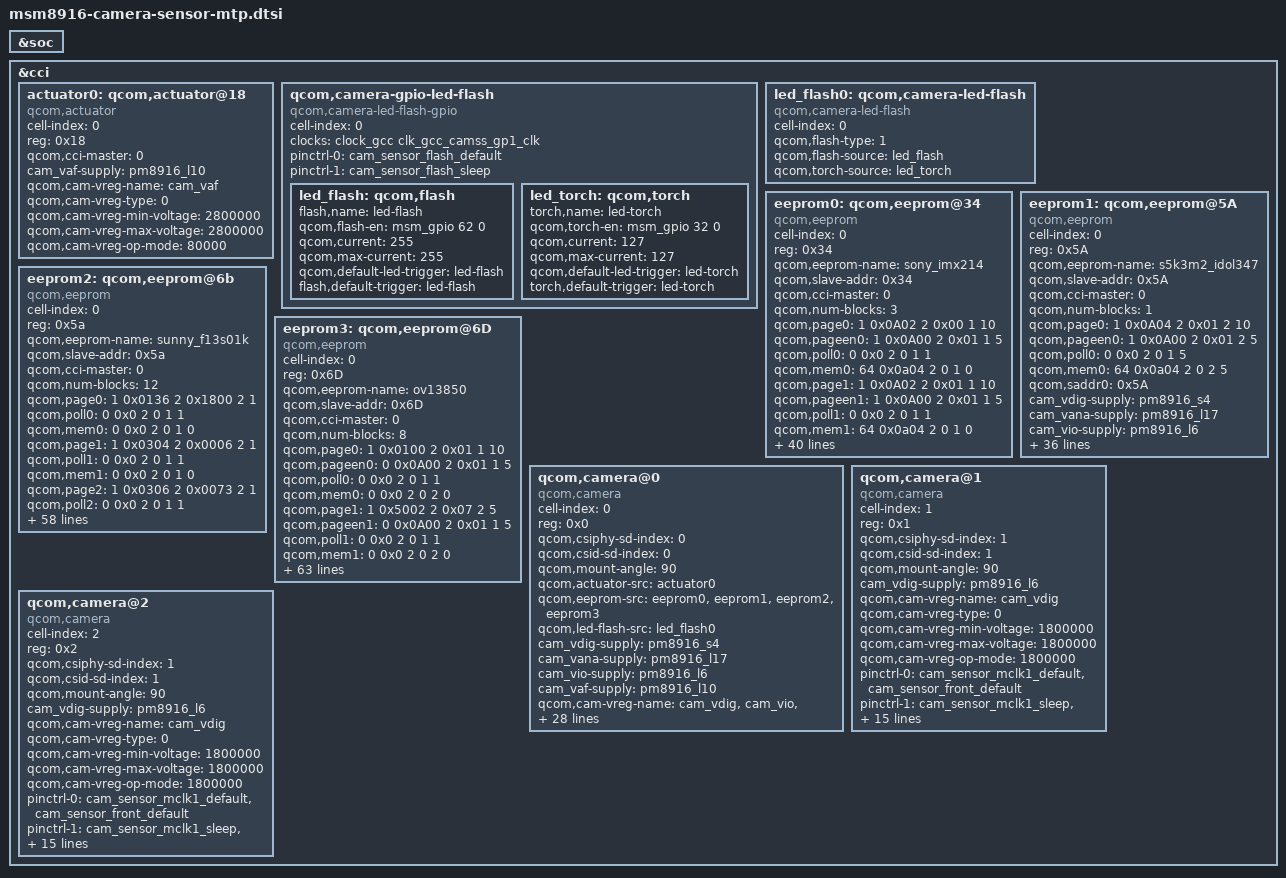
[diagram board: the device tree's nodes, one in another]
/*
 * Copyright (c) 2014-2015, The Linux Foundation. All rights reserved.
 *
 * This program is free software; you can redistribute it and/or modify
 * it under the terms of the GNU General Public License version 2 and
 * only version 2 as published by the Free Software Foundation.
 *
 * This program is distributed in the hope that it will be useful,
 * but WITHOUT ANY WARRANTY; without even the implied warranty of
 * MERCHANTABILITY or FITNESS FOR A PARTICULAR PURPOSE.  See the
 * GNU General Public License for more details.
 */

&soc {
};

&cci {

	actuator0: qcom,actuator@18 {
		cell-index = <0>;
		reg = <0x18>;
		compatible = "qcom,actuator";
		qcom,cci-master = <0>;
		cam_vaf-supply = <&pm8916_l10>;
		qcom,cam-vreg-name = "cam_vaf";
		qcom,cam-vreg-type = <0>;
		qcom,cam-vreg-min-voltage = <2800000>;
		qcom,cam-vreg-max-voltage = <2800000>;
		qcom,cam-vreg-op-mode = <80000>;
	};

	qcom,camera-gpio-led-flash {
		cell-index = <0>;
		compatible = "qcom,camera-led-flash-gpio";
		status = "okay";
 	clocks = <&clock_gcc clk_gcc_camss_gp1_clk>;
		clock-names = "cam_sensor_flash";
		pinctrl-names = "default", "sleep";
		pinctrl-0 = <&cam_sensor_flash_default>;
		pinctrl-1 = <&cam_sensor_flash_sleep>;
		led_flash: qcom,flash {
			flash,name = "led-flash";
			qcom,flash-en = <&msm_gpio 62 0>;
			qcom,current = <255>;
			qcom,max-current = <255>;
            		qcom,default-led-trigger = "led-flash";
			flash,default-trigger = "led-flash";
		};
		led_torch: qcom,torch {
			torch,name = "led-torch";
			qcom,torch-en = <&msm_gpio 32 0>;
			qcom,current = <127>;
			qcom,max-current = <127>;
            		qcom,default-led-trigger = "led-torch";
			torch,default-trigger = "led-torch";
		};
	};

	led_flash0: qcom,camera-led-flash {
		cell-index = <0>;
		compatible = "qcom,camera-led-flash";
		qcom,flash-type = <1>;
		qcom,flash-source = <&led_flash>;
		qcom,torch-source = <&led_torch>;
	};

eeprom0: qcom,eeprom@34 {
		 cell-index = <0>;
		 reg = <0x34>;
		 qcom,eeprom-name = "sony_imx214";
		 compatible = "qcom,eeprom";
		 qcom,slave-addr = <0x34>;
		 qcom,cci-master = <0>;
		 qcom,num-blocks = <3>;

		 qcom,page0 = <1 0x0A02 2 0x00 1 10>;
        	 qcom,pageen0 = <1 0x0A00 2 0x01 1 5>; 
		 qcom,poll0 = <0 0x0 2 0 1 1>;
		 qcom,mem0 = <64 0x0a04 2 0 1 0>;

 		 qcom,page1 = <1 0x0A02 2 0x01 1 10>;
        	 qcom,pageen1 = <1 0x0A00 2 0x01 1 5>; 
		 qcom,poll1 = <0 0x0 2 0 1 1>;
		 qcom,mem1 = <64 0x0a04 2 0 1 0>;

		 qcom,page2 = <1 0x0A02 2 0x02 1 10>;
        	 qcom,pageen2 = <1 0x0A00 2 0x01 1 5>; 
		 qcom,poll2 = <0 0x0 2 0 1 1>;
		 qcom,mem2 = <64 0x0a04 2 0 1 0>;

		cam_vdig-supply = <&pm8916_s4>;
		cam_vana-supply = <&pm8916_l17>;
		cam_vio-supply = <&pm8916_l6>;
		cam_vaf-supply = <&pm8916_l10>;
		 qcom,cam-vreg-name = "cam_vdig", "cam_vio", "cam_vana",
							"cam_vaf";
		qcom,cam-vreg-type = <0 1 0 0>;
		qcom,cam-vreg-min-voltage = <1850000 0 2700000 2800000>;
		qcom,cam-vreg-max-voltage = <1850000 0 2700000 2800000>;
		qcom,cam-vreg-op-mode = <200000 0 80000 100000>;
			pinctrl-names = "cam_default", "cam_suspend";
		pinctrl-0 = <&cam_sensor_mclk0_default
				&cam_sensor_rear_default>;
		pinctrl-1 = <&cam_sensor_mclk0_sleep &cam_sensor_rear_sleep>;
		

		 gpios = <&msm_gpio 26 0>,
			<&msm_gpio 35 0>,
			<&msm_gpio 34 0>,
			<&msm_gpio 109 0>,
			<&msm_gpio 108 0>;
		qcom,gpio-reset = <1>;
		qcom,gpio-standby = <2>;
		qcom,gpio-vdig = <3>;
		qcom,gpio-vana = <4>;
		qcom,gpio-req-tbl-num = <0 1 2 3 4>;
		qcom,gpio-req-tbl-flags = <1 0 0 0 0>;
		qcom,gpio-req-tbl-label = "CAMIF_MCLK",
			"CAM_RESET1",
			"CAM_STANDBY",
			"CAM_GPIO_VDIG",
			"CAM_GPIO_VANA";
			
	 	qcom,cam-power-seq-type = "sensor_gpio","sensor_gpio", "sensor_gpio" , "sensor_clk";
	        qcom,cam-power-seq-val = "sensor_gpio_standby","sensor_gpio_vdig", "sensor_gpio_standby","sensor_cam_mclk";
	        qcom,cam-power-seq-cfg-val = <0 1 1 24000000>;
	        qcom,cam-power-seq-delay = <10 10 10 5>;
 
		
		status = "ok";
        	clocks = <&clock_gcc clk_mclk0_clk_src>,
                	<&clock_gcc clk_gcc_camss_mclk0_clk>;
        	clock-names = "cam_src_clk", "cam_clk"; 

	};

eeprom1: qcom,eeprom@5A {
		 cell-index = <0>;
		 reg = <0x5A>;
		 qcom,eeprom-name = "s5k3m2_idol347";
		 compatible = "qcom,eeprom";
		 qcom,slave-addr = <0x5A>;
		 qcom,cci-master = <0>;
		 qcom,num-blocks = <1>;

		 qcom,page0 = <1 0x0A04 2 0x01 2 10>;
        	 qcom,pageen0 = <1 0x0A00 2 0x01 2 5>; 
		 qcom,poll0 = <0 0x0 2 0 1 5>;
		 qcom,mem0 = <64 0x0a04 2 0 2 5>;
        	 qcom,saddr0 = <0x5A>;


		cam_vdig-supply = <&pm8916_s4>;
		cam_vana-supply = <&pm8916_l17>;
		cam_vio-supply = <&pm8916_l6>;
		cam_vaf-supply = <&pm8916_l10>;
		qcom,cam-vreg-name = "cam_vdig", "cam_vio", "cam_vana",
							"cam_vaf";
		qcom,cam-vreg-type = <0 1 0 0>;
		qcom,cam-vreg-min-voltage = <1100000 0 2700000 2800000>;
		qcom,cam-vreg-max-voltage = <1100000 0 2700000 2800000>;
		qcom,cam-vreg-op-mode = <200000 0 80000 100000>;
			pinctrl-names = "cam_default", "cam_suspend";
		pinctrl-0 = <&cam_sensor_mclk0_default
				&cam_sensor_rear_default>;
		pinctrl-1 = <&cam_sensor_mclk0_sleep &cam_sensor_rear_sleep>;
		

		 gpios = <&msm_gpio 26 0>,
			<&msm_gpio 35 0>,
			<&msm_gpio 34 0>,
			<&msm_gpio 109 0>,
			<&msm_gpio 108 0>;
		qcom,gpio-reset = <1>;
		qcom,gpio-standby = <2>;
		qcom,gpio-vdig = <3>;
		qcom,gpio-vana = <4>;
		qcom,gpio-req-tbl-num = <0 1 2 3 4>;
		qcom,gpio-req-tbl-flags = <1 0 0 0 0>;
		qcom,gpio-req-tbl-label = "CAMIF_MCLK",
			"CAM_RESET1",
			"CAM_STANDBY",
			"CAM_GPIO_VDIG",
			"CAM_GPIO_VANA";
			
	 	qcom,cam-power-seq-type = "sensor_gpio", "sensor_gpio", "sensor_gpio", "sensor_gpio","sensor_gpio", "sensor_clk";
	        qcom,cam-power-seq-val = "sensor_gpio_reset", "sensor_gpio_standby", "sensor_gpio_vdig",  "sensor_gpio_reset","sensor_gpio_standby","sensor_cam_mclk";
	        qcom,cam-power-seq-cfg-val = <0 0 1 1 0 1 1 24000000>;
	        qcom,cam-power-seq-delay = <10 5 5 5 10 5 5 10>;
 
		
		status = "ok";
        	clocks = <&clock_gcc clk_mclk0_clk_src>,
                	<&clock_gcc clk_gcc_camss_mclk0_clk>;
        	clock-names = "cam_src_clk", "cam_clk"; 

	};
eeprom2: qcom,eeprom@6b{
		cell-index = <0>;
		reg = <0x5a>;
		qcom,eeprom-name = "sunny_f13s01k";
		compatible = "qcom,eeprom";
		qcom,slave-addr = <0x5a>;
		qcom,cci-master = <0>;
		qcom,num-blocks = <12>;

		qcom,page0 = <1 0x0136 2 0x1800 2 1>;
		qcom,poll0 = <0 0x0 2 0 1 1>;
		qcom,mem0 = <0 0x0 2 0 1 0>;
		qcom,page1 = <1 0x0304 2 0x0006 2 1>;
		qcom,poll1 = <0 0x0 2 0 1 1>;
		qcom,mem1 = <0 0x0 2 0 1 0>;
		qcom,page2 = <1 0x0306 2 0x0073 2 1>;
		qcom,poll2 = <0 0x0 2 0 1 1>;
		qcom,mem2 = <0 0x0 2 0 1 0>;
		qcom,page3 = <1 0x030c 2 0x0004 2 1>;
		qcom,poll3 = <0 0x0 2 0 1 1>;
		qcom,mem3 = <0 0x0 2 0 2 0>;
		qcom,page4 = <1 0x030e 2 0x0064 2 1>;
		qcom,poll4 = <0 0x0 2 0 1 1>;
		qcom,mem4 = <0 0x0 2 0 1 0>;
		qcom,page5 = <1 0x0302 2 0x0001 2 1>;
		qcom,poll5 = <0 0x0 2 0 1 1>;
		qcom,mem5 = <0 0x0 2 0 1 0>;
		qcom,page6 = <1 0x0300 2 0x0004 2 1>;
		qcom,poll6 = <0 0x0 2 0 1 1>;
		qcom,mem6 = <0 0x0 2 0 1 0>;
		qcom,page7 = <1 0x030a 2 0x0001 2 1>;
		qcom,poll7 = <0 0x0 2 0 1 1>;
		qcom,mem7 = <0 0 2 0 1 0>;
	    qcom,page8 = <1 0x0308 2 0x0008 2 1>;
		qcom,poll8 = <0 0x0 2 0 1 1>;
		qcom,mem8 = <0 0 2 0 1 0>;
        qcom,page9 = <1 0x0100 2 0x0100 2 20>;
		qcom,poll9 = <0 0x0 2 0 1 1>;
		qcom,mem9 = <0 0 2 0 1 0>;
		qcom,page10 = <1 0x0a02 2 0x1f00 2 10>;
		qcom,poll10 = <0 0x0 2 0 1 1>;
		qcom,mem10 = <0 0 2 0 1 0>;
		qcom,page11 = <1 0x0a00 2 0x0100 2 1>;
		qcom,poll11 = <0 0x0 2 0 1 1>;
		qcom,mem11 = <64 0x0a04 2 0 1 0>;

		cam_vdig-supply = <&pm8916_l2>;
		cam_vana-supply = <&pm8916_l17>;
		cam_vio-supply = <&pm8916_l6>;
		qcom,cam-vreg-name = "cam_vdig", "cam_vio", "cam_vana";
		qcom,cam-vreg-type = <0 1 0>;
		qcom,cam-vreg-min-voltage = <1200000 0 2850000>;
		qcom,cam-vreg-max-voltage = <1200000 0 2850000>;
		qcom,cam-vreg-op-mode = <200000 0 80000>;
		pinctrl-names = "cam_default", "cam_suspend";
		pinctrl-0 = <&cam_sensor_mclk0_default &cam_sensor_rear_default>;
		pinctrl-1 = <&cam_sensor_mclk0_sleep &cam_sensor_rear_sleep>;
		gpios = <&msm_gpio 26 0>,
			<&msm_gpio 35 0>,
			<&msm_gpio 34 0>;
		qcom,gpio-reset = <1>;
		qcom,gpio-standby = <2>;
		qcom,gpio-req-tbl-num = <0 1 2>;
		qcom,gpio-req-tbl-flags = <1 0 0>;
		qcom,gpio-req-tbl-label = "CAMIF_MCLK0",
			"MCAM_RESET",
			"MCAM_STANDBY";

		qcom,cam-power-seq-type = "sensor_vreg",
			"sensor_vreg", "sensor_vreg",
			"sensor_clk",
			"sensor_gpio", "sensor_gpio";
		qcom,cam-power-seq-val = "cam_vio",
			"cam_vana", "cam_vdig",
			"sensor_cam_mclk",
			"sensor_gpio_reset",
			"sensor_gpio_standby";
		qcom,cam-power-seq-cfg-val = <1 1 1 24000000 1 1>;
		qcom,cam-power-seq-delay = <1 1 5 5 5 10>;
		status = "ok";
		clocks = <&clock_gcc clk_mclk0_clk_src>,
				<&clock_gcc clk_gcc_camss_mclk0_clk>;
		clock-names = "cam_src_clk", "cam_clk";
	};
eeprom3: qcom,eeprom@6D {
		 cell-index = <0>;
		 reg = <0x6D>;
		 qcom,eeprom-name = "ov13850";
		 compatible = "qcom,eeprom";
		 qcom,slave-addr = <0x6D>;
		 qcom,cci-master = <0>;
		 qcom,num-blocks = <8>;

		 qcom,page0 = <1 0x0100 2 0x01 1 10>;
		 qcom,pageen0 = <0 0x0A00 2 0x01 1 5>;
		 qcom,poll0 = <0 0x0 2 0 1 1>;
		 qcom,mem0 = <0 0x0 2 0 2 0>;
        	 qcom,page1 = <1 0x5002 2 0x07 2 5>;
		 qcom,pageen1 = <0 0x0A00 2 0x01 1 5>; 
		 qcom,poll1 = <0 0x0 2 0 1 1>;
		 qcom,mem1 = <0 0x0 2 0 2 0>;
		 qcom,page2 = <1 0x3d84 2 0xC0 1 10>;
		 qcom,pageen2 = <0 0x0A00 2 0x01 1 5>;
		 qcom,poll2 = <0 0x0 2 0 1 1>;
		 qcom,mem2 = <0 0x0 2 0 2 0>;
		 qcom,page3 = <1 0x3d88 2 0x72 1 10>;
		 qcom,pageen3 = <0 0x0A00 2 0x01 1 5>;
		 qcom,poll3 = <0 0x0 2 0 1 1>;
		 qcom,mem3 = <0 0x0 2 0 2 0>;
		 qcom,page4 = <1 0x3d89 2 0x20 1 10>;
		 qcom,pageen4 = <0 0x0A00 2 0x01 1 5>;
		 qcom,poll4 = <0 0x0 2 0 1 1>;
		 qcom,mem4 = <0 0x0 2 0 2 0>;
		 qcom,page5 = <1 0x3d8A 2 0x73 1 10>;
		 qcom,pageen5 = <0 0x0A00 2 0x01 1 5>;
		 qcom,poll5 = <0 0x0 2 0 1 1>;
		 qcom,mem5 = <0 0x0 2 0 2 0>;
		
		 qcom,page6 = <1 0x3d8B 2 0xBE 1 10>;
		 qcom,pageen6 = <0 0x0A00 2 0x01 1 5>;
		 qcom,poll6 = <0 0x0 2 0 1 1>;
		 qcom,mem6 = <0 0x0 2 0 2 0>;

		 qcom,page7 = <1 0x3d81 2 0x01 1 10>;
		 qcom,pageen7 = <0 0x0A00 2 0x01 1 5>;
		 qcom,poll7 = <0 0x0 2 0 1 5>;
		 qcom,mem7 = <7 0x73B8 2 0 2 5>;
        	

		cam_vdig-supply = <&pm8916_s4>;
		cam_vana-supply = <&pm8916_l17>;
		cam_vio-supply = <&pm8916_l6>;
		cam_vaf-supply = <&pm8916_l10>;
		 qcom,cam-vreg-name = "cam_vdig", "cam_vio", "cam_vana",
							"cam_vaf";
		qcom,cam-vreg-type = <0 1 0 0>;
		qcom,cam-vreg-min-voltage = <1850000 0 2700000 2800000>;
		qcom,cam-vreg-max-voltage = <1850000 0 2700000 2800000>;
		qcom,cam-vreg-op-mode = <200000 0 80000 100000>;
			pinctrl-names = "cam_default", "cam_suspend";
		pinctrl-0 = <&cam_sensor_mclk0_default
				&cam_sensor_rear_default>;
		pinctrl-1 = <&cam_sensor_mclk0_sleep &cam_sensor_rear_sleep>;
		

		 gpios = <&msm_gpio 26 0>,
			<&msm_gpio 35 0>,
			<&msm_gpio 34 0>,
			<&msm_gpio 109 0>,
			<&msm_gpio 108 0>;
		qcom,gpio-reset = <1>;
		qcom,gpio-standby = <2>;
		qcom,gpio-vdig = <3>;
		qcom,gpio-vana = <4>;
		qcom,gpio-req-tbl-num = <0 1 2 3 4>;
		qcom,gpio-req-tbl-flags = <1 0 0 0 0>;
		qcom,gpio-req-tbl-label = "CAMIF_MCLK",
			"CAM_RESET1",
			"CAM_STANDBY",
			"CAM_GPIO_VDIG",
			"CAM_GPIO_VANA";
			
	 	qcom,cam-power-seq-type = "sensor_gpio","sensor_gpio","sensor_gpio","sensor_gpio","sensor_gpio","sensor_gpio" ,"sensor_clk";
	        qcom,cam-power-seq-val = "sensor_gpio_standby","sensor_gpio_reset","sensor_gpio_vana","sensor_gpio_vdig", "sensor_gpio_standby","sensor_gpio_reset","sensor_cam_mclk";

	        qcom,cam-power-seq-cfg-val = <0 0 1 1 1 1 23880000>;
	        qcom,cam-power-seq-delay = <10 10 10 10 15 10 10>;
 
		
		status = "ok";
        	clocks = <&clock_gcc clk_mclk0_clk_src>,
                	<&clock_gcc clk_gcc_camss_mclk0_clk>;
        	clock-names = "cam_src_clk", "cam_clk"; 

	};


	qcom,camera@0 {
		cell-index = <0>;
		compatible = "qcom,camera";
		reg = <0x0>;
		qcom,csiphy-sd-index = <0>;
		qcom,csid-sd-index = <0>;
		qcom,mount-angle = <90>;
		qcom,actuator-src = <&actuator0>;
		qcom,eeprom-src = <&eeprom0 &eeprom1 &eeprom2 &eeprom3>;
		qcom,led-flash-src = <&led_flash0>;
		
		cam_vdig-supply = <&pm8916_s4>;
		cam_vana-supply = <&pm8916_l17>;
		cam_vio-supply = <&pm8916_l6>;
		cam_vaf-supply = <&pm8916_l10>;
		qcom,cam-vreg-name = "cam_vdig", "cam_vio", "cam_vana",
							"cam_vaf";
		qcom,cam-vreg-type = <0 1 0 0>;
		qcom,cam-vreg-min-voltage = <1850000 0 2700000 2800000>;
		qcom,cam-vreg-max-voltage = <1850000 0 2700000 2800000>;
		qcom,cam-vreg-op-mode = <200000 0 80000 100000>;
		pinctrl-names = "cam_default", "cam_suspend";
		pinctrl-0 = <&cam_sensor_mclk0_default
				&cam_sensor_rear_default>;
		pinctrl-1 = <&cam_sensor_mclk0_sleep &cam_sensor_rear_sleep>;
		gpios = <&msm_gpio 26 0>,
			<&msm_gpio 35 0>,
			<&msm_gpio 34 0>,
			<&msm_gpio 109 0>,
			<&msm_gpio 108 0>;
		qcom,gpio-reset = <1>;
		qcom,gpio-standby = <2>;
		qcom,gpio-vdig = <3>;
		qcom,gpio-vana = <4>;
		qcom,gpio-req-tbl-num = <0 1 2 3 4>;
		qcom,gpio-req-tbl-flags = <1 0 0 0 0>;
		qcom,gpio-req-tbl-label = "CAMIF_MCLK",
			"CAM_RESET1",
			"CAM_STANDBY",
			"CAM_GPIO_VDIG",
			"CAM_GPIO_VANA";
		qcom,sensor-position = <0>;
		qcom,sensor-mode = <0>;
		qcom,cci-master = <0>;
		qcom,mclk-23880000;
		status = "ok";
		clocks = <&clock_gcc clk_mclk0_clk_src>,
				<&clock_gcc clk_gcc_camss_mclk0_clk>;
		clock-names = "cam_src_clk", "cam_clk";
	};

	qcom,camera@1 {
		cell-index = <1>;
		compatible = "qcom,camera";
		reg = <0x1>;
		qcom,csiphy-sd-index = <1>;
		qcom,csid-sd-index = <1>;
		qcom,mount-angle = <90>;
		cam_vdig-supply = <&pm8916_l6>;
		qcom,cam-vreg-name = "cam_vdig";
		qcom,cam-vreg-type = <0>;
		qcom,cam-vreg-min-voltage = <1800000>;
		qcom,cam-vreg-max-voltage = <1800000>;
		qcom,cam-vreg-op-mode = <1800000>;
		pinctrl-names = "cam_default", "cam_suspend";
		pinctrl-0 = <&cam_sensor_mclk1_default &cam_sensor_front_default>;
		pinctrl-1 = <&cam_sensor_mclk1_sleep &cam_sensor_front_sleep>;
		gpios = <&msm_gpio 27 0>,
			<&msm_gpio 28 0>,
			<&msm_gpio 120 0>,
			<&msm_gpio 109 0>,
			<&msm_gpio 108 0>;
		qcom,gpio-reset = <1>;
		qcom,gpio-standby = <2>;
		qcom,gpio-vdig = <3>;
		qcom,gpio-vana = <4>;
		qcom,gpio-req-tbl-num = <0 1 2 3 4>;
		qcom,gpio-req-tbl-flags = <1 0 0 0 0>;
		qcom,gpio-req-tbl-label = "CAMIF_MCLK",
			"CAM_RESET",
			"CAM_STANDBY",
			"CAM_GPIO_VDIG",
			"CAM_GPIO_VANA";
		qcom,cci-master = <0>;
		status = "ok";
		clocks = <&clock_gcc clk_mclk1_clk_src>,
				<&clock_gcc clk_gcc_camss_mclk1_clk>;
		clock-names = "cam_src_clk", "cam_clk";
	};
	
	qcom,camera@2 {
		cell-index = <2>;
		compatible = "qcom,camera";
		reg = <0x2>;
		qcom,csiphy-sd-index = <1>;
		qcom,csid-sd-index = <1>;
		qcom,mount-angle = <90>;
		cam_vdig-supply = <&pm8916_l6>;
		qcom,cam-vreg-name = "cam_vdig";
		qcom,cam-vreg-type = <0>;
		qcom,cam-vreg-min-voltage = <1800000>;
		qcom,cam-vreg-max-voltage = <1800000>;
		qcom,cam-vreg-op-mode = <1800000>;
		pinctrl-names = "cam_default", "cam_suspend";
		pinctrl-0 = <&cam_sensor_mclk1_default &cam_sensor_front_default>;
		pinctrl-1 = <&cam_sensor_mclk1_sleep &cam_sensor_front_sleep>;
		gpios = <&msm_gpio 27 0>,
			<&msm_gpio 28 0>,
			<&msm_gpio 120 0>,
			<&msm_gpio 109 0>,
			<&msm_gpio 108 0>;
		qcom,gpio-reset = <1>;
		qcom,gpio-standby = <2>;
		qcom,gpio-vdig = <3>;
		qcom,gpio-vana = <4>;
		qcom,gpio-req-tbl-num = <0 1 2 3 4>;
		qcom,gpio-req-tbl-flags = <1 0 0 0 0>;
		qcom,gpio-req-tbl-label = "CAMIF_MCLK",
			"CAM_RESET",
			"CAM_STANDBY",
			"CAM_GPIO_VDIG",
			"CAM_GPIO_VANA";
		qcom,cci-master = <0>;
		status = "ok";
		clocks = <&clock_gcc clk_mclk1_clk_src>,
				<&clock_gcc clk_gcc_camss_mclk1_clk>;
		clock-names = "cam_src_clk", "cam_clk";
	};
};
